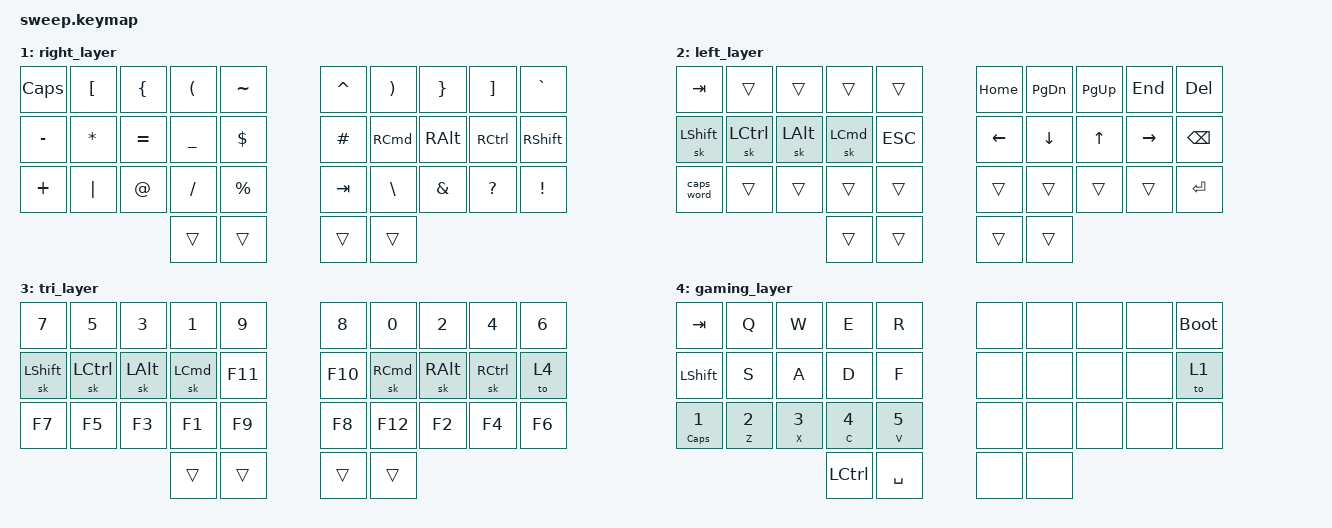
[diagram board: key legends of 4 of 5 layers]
// Copyright (c) 2022 The ZMK Contributors
// SPDX-License-Identifier: MIT

#include <behaviors.dtsi>
#include <dt-bindings/zmk/keys.h>
#include <dt-bindings/zmk/bt.h>

// Home row mods macro
#define HRML(k1,k2,k3,k4) &ht LSHFT k1  &ht LCTRL k2  &ht LALT k3  &ht LGUI k4
#define HRMR(k1,k2,k3,k4) &ht RGUI k1  &ht RALT k2  &ht RCTRL k3  &ht RSHFT k4

/ {
    behaviors {
        ht: hold_tap {
            compatible = "zmk,behavior-hold-tap";
            #binding-cells = <2>;
            flavor = "tap-preferred";
            tapping-term-ms = <220>;
            quick-tap-ms = <150>;
            require-prior-idle-ms = <100>;
            bindings = <&kp>, <&kp>;
        };
    };
    behaviors {
        td2: tap_dance_2 {
            compatible = "zmk,behavior-tap-dance";
            #binding-cells = <0>;
            tapping-term-ms = <100>;
            bindings = <&kp>, <&kp>;
        };
    };

    conditional_layers {
        compatible = "zmk,conditional-layers";
        tri_layer {
            if-layers = <1 2>;
            then-layer = <3>;
        };
    };

    keymap {
        compatible = "zmk,keymap";
        default_layer {
            bindings = <
        //╭──────────┬──────────┬──────────┬──────────┬──────────╮   ╭──────────┬──────────┬──────────┬──────────┬──────────╮
        //│  Q       │  W       │  E       │  R       │  T       │   │  Y       │  U       │  I       │  O       │  P       │
            &kp Q      &kp W      &kp E      &kp R      &kp T          &kp Y      &kp U      &kp I      &kp O      &kp P
        //├──────────┼──────────┼──────────┼──────────┼──────────┤   ├──────────┼──────────┼──────────┼──────────┼──────────┤
        //│  A       │  S       │  D       │  F       │  G       │   │  H       │  J       │  K       │  L       │ ' "      │
            HRML(A,        S,         D,         F)     &kp G          &kp H      HRMR(J,        K,         L,        SQT)
        //├──────────┼──────────┼──────────┼──────────┼──────────┤   ├──────────┼──────────┼──────────┼──────────┼──────────┤
        //│  Z       │  X       │  C       │  V       │  B       │   │  N       │  M       │ ,        │ .        │ ;        │
            &kp Z      &kp X      &kp C      &kp V      &kp B          &kp N      &kp M      &kp COMMA  &kp DOT    &kp SEMI
        //╰──────────┴──────────┴──────────┼──────────┼──────────┤   ├──────────┼──────────┼──────────┴──────────┴──────────╯
                                             &lt 2 TAB  &kp LSHIFT     &kp SPACE  &td 1 CAPS 
        //                                 ╰──────────┴──────────╯   ╰──────────┴──────────╯
            >;
        };

        right_layer {
            bindings = <
        //╭──────────┬──────────┬──────────┬──────────┬──────────╮   ╭──────────┬──────────┬──────────┬──────────┬──────────╮
        //│          │  [       │  {       │  (       │  ~       │   │  ^       │  )       │  }       │  ]       │  ~       │
            &kp CAPS  &kp LBKT   &kp LBRC   &kp LPAR   &kp TILDE      &kp CARET  &kp RPAR   &kp RBRC   &kp RBKT   &kp GRAVE
        //├──────────┼──────────┼──────────┼──────────┼──────────┤   ├──────────┼──────────┼──────────┼──────────┼──────────┤
        //│  -       │  *       │  =       │  _       │  $       │   │  #       │          │          │          │          │
            &kp MINUS  &kp ASTRK  &kp EQUAL  &kp UNDER  &kp DLLR       &kp HASH   &kp RCMD   &kp RALT   &kp RCTRL  &kp RSHIFT
        //├──────────┼──────────┼──────────┼──────────┼──────────┤   ├──────────┼──────────┼──────────┼──────────┼──────────┤
        //│  +       │  |       │ @        │ /        │ %        │   │          │  \       │  &       │  ?       │  !       │
            &kp PLUS   &kp PIPE   &kp AT     &kp FSLH   &kp PRCNT      &kp TAB    &kp BSLH   &kp AMPS   &kp QMARK  &kp EXCL
        //╰──────────┴──────────┴──────────┼──────────┼──────────┤   ├──────────┼──────────┼──────────┴──────────┴──────────╯
                                             &trans     &trans         &trans     &trans
        //                                 ╰──────────┴──────────╯   ╰──────────┴──────────╯
            >;
        };

        left_layer {
            bindings = <
        //╭──────────┬──────────┬──────────┬──────────┬──────────╮   ╭──────────┬──────────┬──────────┬──────────┬──────────╮
        //│ TAB      │          │          │          │          │   │ HOME     │ PAGE DN  │ PAGE UP  │ END      │          │
            &kp TAB    &trans     &trans     &trans     &trans         &kp HOME   &kp PG_DN  &kp PG_UP  &kp END    &kp DEL
        //├──────────┼──────────┼──────────┼──────────┼──────────┤   ├──────────┼──────────┼──────────┼──────────┼──────────┤
        //│          │          │          │          │          │   │ LEFT     │ DOWN     │ UP       │ RIGHT    │          │
            &sk LSHIFT &sk LCTRL  &sk LALT   &sk LCMD   &ESC           &kp LEFT   &kp DOWN   &kp UP     &kp RIGHT  &kp BSPC
        //├──────────┼──────────┼──────────┼──────────┼──────────┤   ├──────────┼──────────┼──────────┼──────────┼──────────┤
        //│ CAPS     │          │          │          │          │   │          │          │          │          │          │
           &caps_word  &trans     &trans     &trans     &trans         &trans     &trans     &trans     &trans     &kp ENTER
        //╰──────────┴──────────┴──────────┼──────────┼──────────┤   ├──────────┼──────────┼──────────┴──────────┴──────────╯
                                             &trans     &trans         &trans     &trans
        //                                 ╰──────────┴──────────╯   ╰──────────┴──────────╯
            >;
        };

        tri_layer {
            bindings = <
        //╭──────────┬──────────┬──────────┬──────────┬──────────╮   ╭──────────┬──────────┬──────────┬──────────┬──────────╮
        //│          │          │          │          │          │   │          │          │          │          |          |
            &kp 7      &kp 5      &kp 3      &kp 1      &kp 9          &kp 8      &kp 0      &kp 2      &kp 4      &kp 6
        //├──────────┼──────────┼──────────┼──────────┼──────────┤   ├──────────┼──────────┼──────────┼──────────┼──────────┤
        //           │          │          │          │          │   │          │          │          |          |
           &sk LSHIFT &sk LCTRL   &sk LALT   &sk LCMD   &kp F11        &kp F10    &sk RCMD   &sk RALT   &sk RCTRL  &to 4  
        //├──────────┼──────────┼──────────┼──────────┼──────────┤   ├──────────┼──────────┼──────────┼──────────┼──────────┤
        //│          │          │          │          │      │   │   │          │          │          │          │
            &kp F7     &kp F5     &kp F3     &kp F1     &kp F9         &kp F8     &kp F12    &kp F2     &kp F4     &kp F6
        //╰──────────┴──────────┴──────────┼──────────┼──────────┤   ├──────────┼──────────┼──────────┴──────────┴──────────╯
                                             &trans     &trans         &trans     &trans
        //                                 ╰──────────┴──────────╯   ╰──────────┴──────────╯
            >;
        };


        gaming_layer {
            bindings = <
            &kp TAB      &kp Q      &kp W      &kp E      &kp R          &none      &none      &none      &none      &bootloader
            &kp LSHFT    &kp S      &kp A      &kp D      &kp F          &none      &none      &none      &none      &to 1
            &ht CAPS 1   &ht Z 2    &ht X 3    &ht C 4    &ht V 5        &none      &none      &none      &none      &none
                                               &kp LCTRL  &kp SPACE      &none      &none
            >;
        };

    };
};
